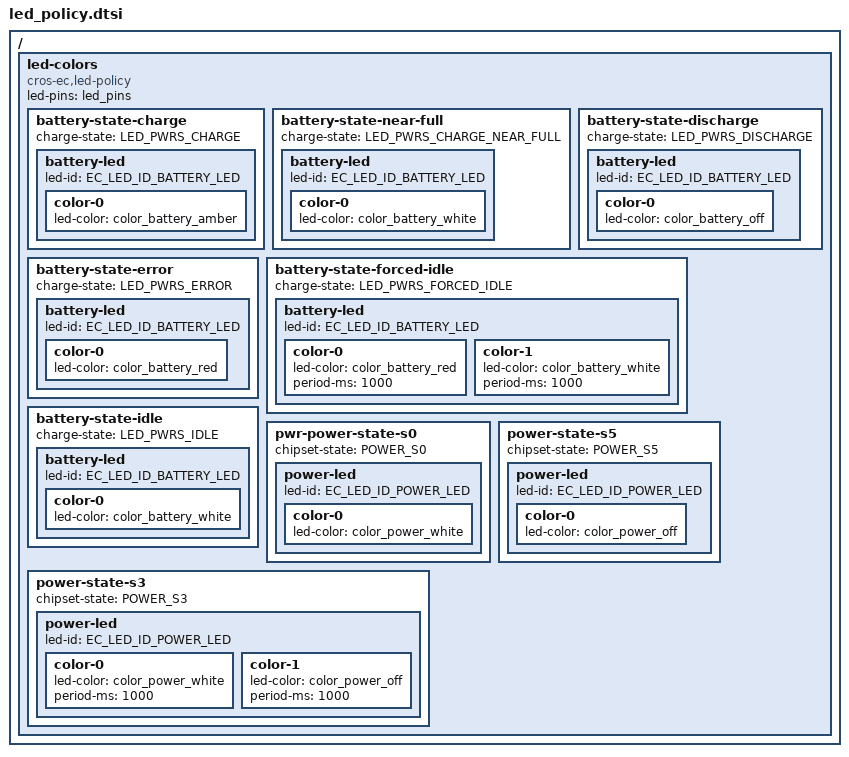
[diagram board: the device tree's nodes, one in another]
#include <dt-bindings/battery.h>

/ {
	led-colors {
		compatible = "cros-ec,led-policy";
		led-pins = <&led_pins>;

		battery-state-charge {
			charge-state = "LED_PWRS_CHARGE";

			battery-led {
				led-id = "EC_LED_ID_BATTERY_LED";
				color-0 {
					led-color = <&color_battery_amber>;
				};
			};
		};

		battery-state-near-full {
			charge-state = "LED_PWRS_CHARGE_NEAR_FULL";

			battery-led {
				led-id = "EC_LED_ID_BATTERY_LED";
				color-0 {
					led-color = <&color_battery_white>;
				};
			};
		};

		battery-state-discharge {
			charge-state = "LED_PWRS_DISCHARGE";

			battery-led {
				led-id = "EC_LED_ID_BATTERY_LED";
				color-0 {
					led-color = <&color_battery_off>;
				};
			};
		};

		battery-state-error {
			charge-state = "LED_PWRS_ERROR";

			battery-led {
				led-id = "EC_LED_ID_BATTERY_LED";
				color-0 {
					led-color = <&color_battery_red>;
				};
			};
		};

		/* force idle mode */
		battery-state-forced-idle {
			charge-state = "LED_PWRS_FORCED_IDLE";

			battery-led {
				led-id = "EC_LED_ID_BATTERY_LED";
				/* Red 1 sec, White 1 sec */
				color-0 {
					led-color = <&color_battery_red>;
					period-ms = <1000>;
				};

				color-1 {
					led-color = <&color_battery_white>;
					period-ms = <1000>;
				};
			};
		};

		battery-state-idle {
			charge-state = "LED_PWRS_IDLE";

			battery-led {
				led-id = "EC_LED_ID_BATTERY_LED";
				color-0 {
					led-color = <&color_battery_white>;
				};
			};
		};

		pwr-power-state-s0 {
			chipset-state = "POWER_S0";

			power-led {
				led-id = "EC_LED_ID_POWER_LED";
				color-0 {
					led-color = <&color_power_white>;
				};
			};
		};

		power-state-s3 {
			chipset-state = "POWER_S3";

			power-led {
				led-id = "EC_LED_ID_POWER_LED";
				/* white LED - on 1 sec, off 1 sec */
				color-0 {
					led-color = <&color_power_white>;
					period-ms = <1000>;
				};

				color-1 {
					led-color = <&color_power_off>;
					period-ms = <1000>;
				};
			};
		};

		power-state-s5 {
			chipset-state = "POWER_S5";

			power-led {
				led-id = "EC_LED_ID_POWER_LED";
				color-0 {
					led-color = <&color_power_off>;
				};
			};
		};
	};
};
